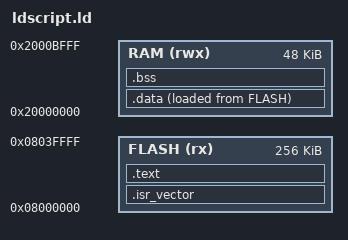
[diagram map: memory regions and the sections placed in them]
ENTRY(Reset_Handler)

MEMORY
{
    FLASH (rx)  : ORIGIN = 0x08000000, LENGTH = 256K
    RAM (rwx)   : ORIGIN = 0x20000000, LENGTH = 48K
}

_estack = 0x2000c000;

SECTIONS
{
    .isr_vector :
    {
        . = ALIGN(4);
        KEEP(*(.isr_vector))
        . = ALIGN(4);
    } >FLASH

    .text :
    {
        . = ALIGN(4);
        _stext = .;
        *(.text)
        *(.text*)
        *(.rodata)
        *(.rodata*)
        . = ALIGN(4);
        _etext = .;
    } >FLASH

    .data :
    {
        _sdata = .;
        *(.data)
        *(.data*)
        . = ALIGN(4);
        _edata = .;
    } >RAM AT>FLASH

    _sidata = LOADADDR(.data);

    .bss :
    {
        _sbss = .;
        *(.bss)
        *(.bss*)
        *(COMMON)
        . = ALIGN(4);
        _ebss = .;
    } >RAM
}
